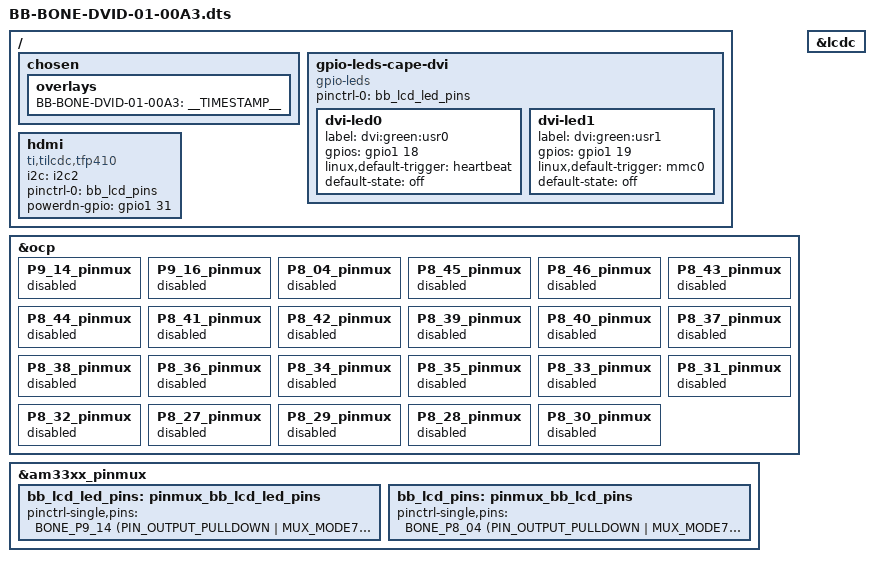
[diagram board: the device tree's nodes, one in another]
/*
 * Copyright (C) 2012 Texas Instruments Incorporated - http://www.ti.com/
 *
 * This program is free software; you can redistribute it and/or modify
 * it under the terms of the GNU General Public License version 2 as
 * published by the Free Software Foundation.
 */
/dts-v1/;
/plugin/;

#include <dt-bindings/board/am335x-bbw-bbb-base.h>
#include <dt-bindings/pinctrl/am33xx.h>

/ {
	/*
	 * Helper to show loaded overlays under: /proc/device-tree/chosen/overlays/
	 */
	fragment@0 {
		target-path="/";
		__overlay__ {

			chosen {
				overlays {
					BB-BONE-DVID-01-00A3 = __TIMESTAMP__;
				};
			};
		};
	};

	/*
	 * Free up the pins used by the cape from the pinmux helpers.
	 */
	fragment@1 {
		target = <&ocp>;
		__overlay__ {
			P9_14_pinmux { status = "disabled"; };	/* P9_14: gpmc_a2.gpio1_18 */
			P9_16_pinmux { status = "disabled"; };	/* P9_16: gpmc_a3.gpio1_19 */

			P8_04_pinmux { status = "disabled"; };	/* P8_04: gpmc_ad7.gpio1_7, OUTPUT | MODE7 - DVIPDn */

			P8_45_pinmux { status = "disabled"; };	/* P8_45: lcd_data0.lcd_data0 */
			P8_46_pinmux { status = "disabled"; };	/* P8_46: lcd_data1.lcd_data1 */
			P8_43_pinmux { status = "disabled"; };	/* P8_43: lcd_data2.lcd_data2 */
			P8_44_pinmux { status = "disabled"; };	/* P8_44: lcd_data3.lcd_data3 */
			P8_41_pinmux { status = "disabled"; };	/* P8_41: lcd_data4.lcd_data4 */
			P8_42_pinmux { status = "disabled"; };	/* P8_42: lcd_data5.lcd_data5 */
			P8_39_pinmux { status = "disabled"; };	/* P8_39: lcd_data6.lcd_data6 */
			P8_40_pinmux { status = "disabled"; };	/* P8_40: lcd_data7.lcd_data7 */
			P8_37_pinmux { status = "disabled"; };	/* P8_37: lcd_data8.lcd_data8 */
			P8_38_pinmux { status = "disabled"; };	/* P8_38: lcd_data9.lcd_data9 */
			P8_36_pinmux { status = "disabled"; };	/* P8_36: lcd_data10.lcd_data10 */
			P8_34_pinmux { status = "disabled"; };	/* P8_34: lcd_data11.lcd_data11 */
			P8_35_pinmux { status = "disabled"; };	/* P8_35: lcd_data12.lcd_data12 */
			P8_33_pinmux { status = "disabled"; };	/* P8_33: lcd_data13.lcd_data13 */
			P8_31_pinmux { status = "disabled"; };	/* P8_31: lcd_data14.lcd_data14 */
			P8_32_pinmux { status = "disabled"; };	/* P8_32: lcd_data15.lcd_data15 */

			P8_27_pinmux { status = "disabled"; };	/* P8_27: lcd_vsync.lcd_vsync */
			P8_29_pinmux { status = "disabled"; };	/* P8_29: lcd_hsync.lcd_hsync */
			P8_28_pinmux { status = "disabled"; };	/* P8_28: lcd_pclk.lcd_pclk */
			P8_30_pinmux { status = "disabled"; };	/* P8_30: lcd_ac_bias_en.lcd_ac_bias_en */
		};
	};

	fragment@2 {
		target = <&am33xx_pinmux>;
		__overlay__ {

			bb_lcd_led_pins: pinmux_bb_lcd_led_pins {
				pinctrl-single,pins = <
					BONE_P9_14 (PIN_OUTPUT_PULLDOWN | MUX_MODE7) /* P9_14: gpmc_a2.gpio1_18 */
					BONE_P9_16 (PIN_OUTPUT_PULLDOWN | MUX_MODE7) /* P9_16: gpmc_a3.gpio1_19 */
				>;
			};

			bb_lcd_pins: pinmux_bb_lcd_pins {
				pinctrl-single,pins = <

					/* Warning, P8_04 is mmc1_dat7 on BBB's eMMC, thus the output will flicker, unless eMMC is disabled... */
					BONE_P8_04 (PIN_OUTPUT_PULLDOWN | MUX_MODE7) /* P8_04: gpmc_ad7.gpio1_7, OUTPUT | MODE7 - DVIPDn */

					BONE_P8_45 (PIN_OUTPUT | MUX_MODE0) /* P8_45: lcd_data0.lcd_data0 */
					BONE_P8_46 (PIN_OUTPUT | MUX_MODE0) /* P8_46: lcd_data1.lcd_data1 */
					BONE_P8_43 (PIN_OUTPUT | MUX_MODE0) /* P8_43: lcd_data2.lcd_data2 */
					BONE_P8_44 (PIN_OUTPUT | MUX_MODE0) /* P8_44: lcd_data3.lcd_data3 */
					BONE_P8_41 (PIN_OUTPUT | MUX_MODE0) /* P8_41: lcd_data4.lcd_data4 */
					BONE_P8_42 (PIN_OUTPUT | MUX_MODE0) /* P8_42: lcd_data5.lcd_data5 */
					BONE_P8_39 (PIN_OUTPUT | MUX_MODE0) /* P8_39: lcd_data6.lcd_data6 */
					BONE_P8_40 (PIN_OUTPUT | MUX_MODE0) /* P8_40: lcd_data7.lcd_data7 */
					BONE_P8_37 (PIN_OUTPUT | MUX_MODE0) /* P8_37: lcd_data8.lcd_data8 */
					BONE_P8_38 (PIN_OUTPUT | MUX_MODE0) /* P8_38: lcd_data9.lcd_data9 */
					BONE_P8_36 (PIN_OUTPUT | MUX_MODE0) /* P8_36: lcd_data10.lcd_data10 */
					BONE_P8_34 (PIN_OUTPUT | MUX_MODE0) /* P8_34: lcd_data11.lcd_data11 */
					BONE_P8_35 (PIN_OUTPUT | MUX_MODE0) /* P8_35: lcd_data12.lcd_data12 */
					BONE_P8_33 (PIN_OUTPUT | MUX_MODE0) /* P8_33: lcd_data13.lcd_data13 */
					BONE_P8_31 (PIN_OUTPUT | MUX_MODE0) /* P8_31: lcd_data14.lcd_data14 */
					BONE_P8_32 (PIN_OUTPUT | MUX_MODE0) /* P8_32: lcd_data15.lcd_data15 */

					BONE_P8_27 (PIN_OUTPUT | MUX_MODE0) /* P8_27: lcd_vsync.lcd_vsync */
					BONE_P8_29 (PIN_OUTPUT | MUX_MODE0) /* P8_29: lcd_hsync.lcd_hsync */
					BONE_P8_28 (PIN_OUTPUT | MUX_MODE0) /* P8_28: lcd_pclk.lcd_pclk */
					BONE_P8_30 (PIN_OUTPUT | MUX_MODE0) /* P8_30: lcd_ac_bias_en.lcd_ac_bias_en */
				>;
			};
		};
	};

	fragment@3 {
		target-path="/";
		__overlay__ {
			gpio-leds-cape-dvi {
				compatible = "gpio-leds";
				pinctrl-names = "default";
				pinctrl-0 = <&bb_lcd_led_pins>;

				dvi-led0 {
					label = "dvi:green:usr0";
					gpios = <&gpio1 18 0>;
					linux,default-trigger = "heartbeat";
					default-state = "off";
				};

				dvi-led1 {
					label = "dvi:green:usr1";
					gpios = <&gpio1 19 0>;
					linux,default-trigger = "mmc0";
					default-state = "off";
				};
			};

			hdmi {
				compatible = "ti,tilcdc,tfp410";
				i2c = <&i2c2>;
				pinctrl-names = "default";
				pinctrl-0 = <&bb_lcd_pins>;
				powerdn-gpio = <&gpio1 31 0>;
				status = "okay";
			};
		};
	};

	fragment@4 {
		target = <&lcdc>;
		__overlay__ {
			status = "okay";
		};
	};
};
